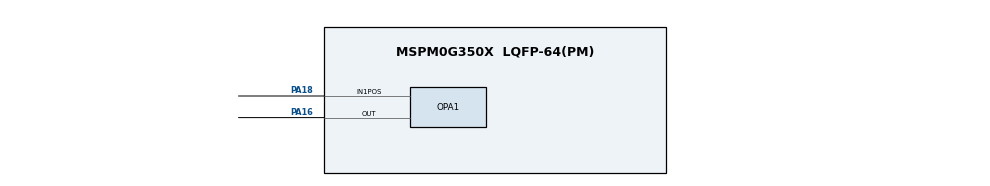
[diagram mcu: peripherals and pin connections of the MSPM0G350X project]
/**
 * @cliArgs --device "MSPM0G350X" --part "Default" --package "LQFP-64(PM)" --product "mspm0_sdk@2.08.00.02"
 * @versions {"tool":"1.25.0+4268"}
 */

/**
 * Import the modules used in this configuration.
 */
const Board         = scripting.addModule("/ti/driverlib/Board");
const OPA           = scripting.addModule("/ti/driverlib/OPA", {}, false);
const OPA1          = OPA.addInstance();
const SYSCTL        = scripting.addModule("/ti/driverlib/SYSCTL");
const ProjectConfig = scripting.addModule("/ti/project_config/ProjectConfig");

/**
 * Write custom configuration values to the imported modules.
 */

OPA1.$name                        = "OPA_0";
OPA1.cfg0PSELChannel              = "IN1_POS";
OPA1.cfg0NSELChannel              = "RTAP";
OPA1.cfg0MSELChannel              = "GND";
OPA1.cfg0OutputPin                = "ENABLED";
OPA1.advBW                        = "HIGH";
OPA1.cfg0Gain                     = "N7_P8";
OPA1.In1PosPinConfig.$name        = "ti_driverlib_gpio_GPIOPinGeneric0";
OPA1.peripheral.$assign           = "OPA1";
OPA1.peripheral.In1PosPin.$assign = "PA18";
OPA1.peripheral.OutPin.$assign    = "PA16";
OPA1.OutPinConfig.$name           = "ti_driverlib_gpio_GPIOPinGeneric1";

SYSCTL.clockTreeEn           = true;
SYSCTL.forceDefaultClkConfig = true;

/**
 * Pinmux solution for unlocked pins/peripherals. This ensures that minor changes to the automatic solver in a future
 * version of the tool will not impact the pinmux you originally saw.  These lines can be completely deleted in order to
 * re-solve from scratch.
 */
Board.peripheral.$suggestSolution          = "DEBUGSS";
Board.peripheral.swclkPin.$suggestSolution = "PA20";
Board.peripheral.swdioPin.$suggestSolution = "PA19";
